# MDR1986VE81 register map
Vendor: Milandr; Series: ARMCM4; File version: 2.0
ARM 32-bit Cortex-M4 Microcontroller based device, CPU clock up to 60MHz, etc.
CPU: CM4 r0p0, little endian, MPU, FPU, 3 interrupt priority bits
Registers are 32-bit, read-write, reset 0x0 unless marked. A register's access mark holds for its fields unless they carry their own. Offsets are from the block's base; lines under a group give offsets from that group; [hi:lo] are bit positions; {n}, {i} and the like mark numbered series; 'fields as' and 'values as' point back to an identical list; <NAME> marks a mode.

## Memory map
0x21000000 MDR_ETH1 size 0x3A — Ethernet Control
0x40000000 MDR_RST_CLOCK size 0x1D0 — CLock Control
0x40001000 MDR_BKP size 0x184 — Backup and RTC Control
0x40006000 MDR_SRAM size 0x28 — OTP_SRAM Memory Control
0x40080000 MDR_PORTA size 0x8C — PORTA
0x40081000 MDR_PORTB size 0x8C — PORTB
0x40082000 MDR_PORTC size 0x8C — PORTC
0x40083000 MDR_PORTD size 0x8C — PORTD
0x40084000 MDR_PORTE size 0x8C — PORTE
0x4008A000 MDR_TIMER1 size 0x90 — TIMER Control
0x4008B000 MDR_TIMER2 size 0x90
0x4008C000 MDR_TIMER3 size 0x90
0x4008D000 MDR_TIMER4 size 0x90
0x40090000 MDR_CAN1 size 0x600 — CAN Control
0x40095000 MDR_SSP1 size 0x28 — Synchronous Serial Port
0x40099000 MDR_UART1 size 0x84 — UART Control
0x4009A000 MDR_UART2 size 0x84
0xE0042000 MDR_DMA size 0x70 — DMA Controler

## MDR_SRAM — OTP_SRAM Memory Control
Base 0x40006000
0x00 KEY — Unlock block register
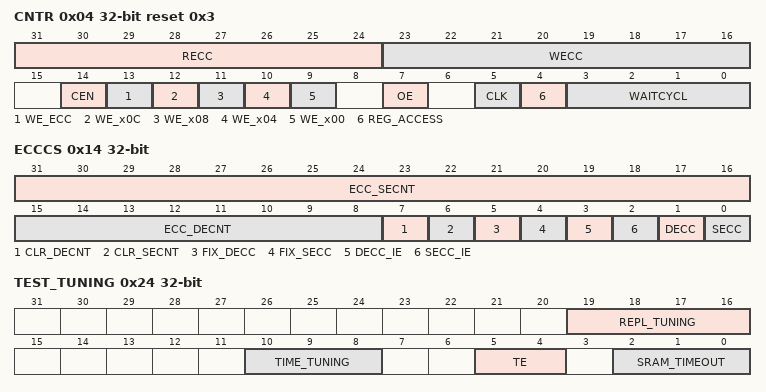
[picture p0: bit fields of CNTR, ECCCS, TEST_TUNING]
0x04 CNTR reset 0x3 — Control register
  [31:24] RECC — ECC after read with RDATA
  [23:16] WECC — ECC for write with WDATA
  [14] CEN — CE for SRAM
    0=Active (Memory selected); 1=Ivactive (Memory not selected)
  [13] WE_ECC — WE for SRAM addr ECC
    0=Write Enable; 1=Ivactive (Write Disable)
  [12] WE_x0C — WE for SRAM addr section 0x0C
    0=Write Enable; 1=Ivactive (Write Disable)
  [11] WE_x08 — WE for SRAM addr section 0x08
    0=Write Enable; 1=Ivactive (Write Disable)
  [10] WE_x04 — WE for SRAM addr section 0x04
    0=Write Enable; 1=Ivactive (Write Disable)
  [9] WE_x00 — WE for SRAM addr section 0x00
    0=Write Enable; 1=Ivactive (Write Disable)
  [7] OE — OE for SRAM
    0=Read Enable; 1=Ivactive (Read Disable)
  [5] CLK — Rise front to write or read
    0=Low (Logic 0); 1=High (Logic 1)
  [4] REG_ACCESS — OTP Access Delay
    0=Off (Bus access); 1=On (Access through registers)
  [3:0] WAITCYCL — OTP Access Delay
    0=Forbiden value; 1=20MHz83 (Delay for clock up to 20.83 MHz); 2=41MHz66 (Delay for clock up to 41.66 MHz); 3=62MHz5 (Delay for clock up to 62.5 MHz); 4=83MHz33 (Delay for clock up to 83.33 MHz); 5=100MHz (Delay for clock up to 100 MHz)
0x08 ADR — Access address
0x0C WDATA — Data to write
0x10 RDATA — Read out data
0x14 ECCCS — Control-Status Register
  [31:16] ECC_SECNT — SE Events Counter
  [15:8] ECC_DECNT — DE Events Counter
  [7] CLR_DECNT — Clear DE counter
    0=Inactive (No Action); 1=Clear (Action)
  [6] CLR_SECNT — Clear SE counter
    0=Inactive (No Action); 1=Clear (Action)
  [5] FIX_DECC — Log DE to ECCADR, ECCDATA, ECCECC
    0=Off (Disable); 1=On (Enable)
  [4] FIX_SECC — Log SE to ECCADR, ECCDATA, ECCECC
    0=Off (Disable); 1=On (Enable)
  [3] DECC_IE — DoubleError IRQ Enable
    0=Off (Disable); 1=On (Enable)
  [2] SECC_IE — SingleError IRQ Enable
    0=Off (Disable); 1=On (Enable)
  [1] DECC — DoubleError flag
    0=Off (No Event detected); 1=On (Event detected)
  [0] SECC — SingleError flag
    0=Off (No Event detected); 1=On (Event detected)
0x18 ECCADR — Last error address without correction
0x1C ECCDATA — Last error data without correction
0x20 ECCECC (reset mask 0xFF) — Last error ECC without correction
0x24 TEST_TUNING (reset mask 0xF0733) — Access Memory Tuning register
  [19:16] REPL_TUNING — Bit Hi_Level Read Resistance
    0=Repl_EasyMax (Read Resistance); 1=Repl_Easy1 (Read Resistance); 2=Repl_Norm (Read Resistance); {v}=Repl_Hard{v-2} (Read Resistance) (v=3..14); 15=Repl_HardMax (Read Resistance)
  [10:8] TIME_TUNING — Timeouts to read bit
    0=Time_HardMax (Read Timeout); 1=Time_Hard2 (Read Timeout); 2=Time_Hard1 (Read Timeout); 3=Time_Norm (Read Timeout); 4=Time_Easy1 (Read Timeout); 5=Time_Easy2 (Read Timeout); 6=Time_Easy3 (Read Timeout); 7=Time_EasyMax (Read Timeout)
  [5:4] TE — Select Test Mode
    0=Off (Normal Operation); 1=Test_1 (Test Mode 1); 2=Test_2 (Test Mode 2); 3=Test_3 (Test Mode 3)
  [2:0] SRAM_TIMEOUT — Timeouts to read SRAM
    0=Time_HardMax (SRAM Read Timeout); 1=Time_Hard2 (SRAM Read Timeout); 2=Time_Norm (SRAM Read Timeout); {v}=Time_Easy{v-2} (SRAM Read Timeout) (v=3..6); 7=Time_EasyMax (SRAM Read Timeout)
